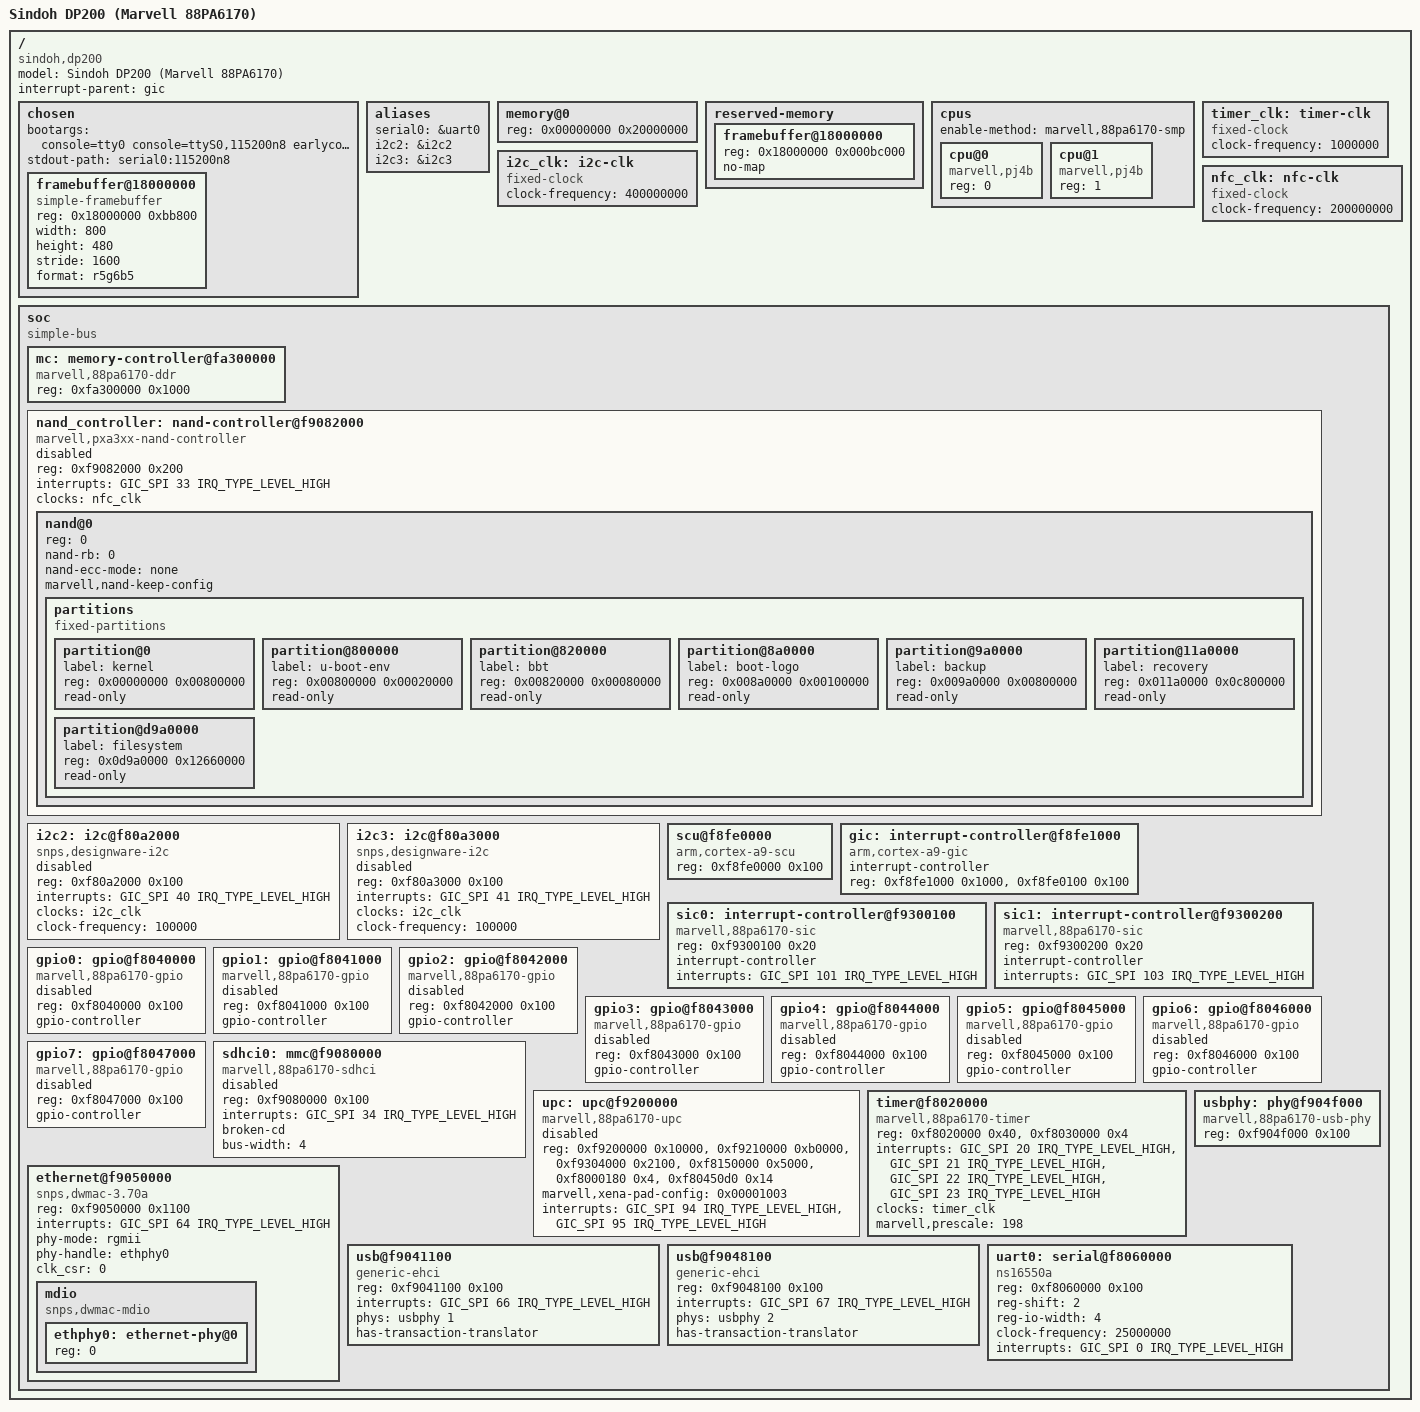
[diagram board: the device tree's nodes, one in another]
// SPDX-License-Identifier: GPL-2.0
/*
 * Sindoh DP200 3D printer, Marvell 88PA6170 SoC: milestone 1 of the
 * mainline route (klipper_port/docs/no_gpl_plan.md). One CPU, GIC, SoC
 * timer, UART0, built-in initramfs.
 *
 * Addresses and IRQs come from the vendor 3.2 kernel image
 * (tools/kernel_re/, docs/kernel/vendor_hwtables.txt). The vendor kernel
 * numbers IRQs as GIC IDs, so GIC_SPI n = vendor IRQ n - 32.
 *
 * Boot: zImage with this DTB appended (ARM_APPENDED_DTB +
 * ARM_ATAG_DTB_COMPAT), wrapped by mkimage for "bootm" in U-Boot 2011.09.
 * U-Boot's bootargs are appended to the bootargs below.
 */
/dts-v1/;

#include <dt-bindings/interrupt-controller/arm-gic.h>
#include <dt-bindings/interrupt-controller/irq.h>

/ {
	model = "Sindoh DP200 (Marvell 88PA6170)";
	compatible = "sindoh,dp200", "marvell,88pa6170";
	#address-cells = <1>;
	#size-cells = <1>;
	interrupt-parent = <&gic>;

	chosen {
		#address-cells = <1>;
		#size-cells = <1>;
		ranges;

		/* console=ttyS0 last: it stays /dev/console, tty0 is the panel */
		bootargs = "console=tty0 console=ttyS0,115200n8 earlycon=uart8250,mmio32,0xf8060000 rdinit=/init panic=10";
		stdout-path = "serial0:115200n8";

		/*
		 * The boot-logo buffer U-Boot set up and the LCD controller
		 * (0xf9070000) still scans: 800x480 RGB565, the panel mounted
		 * in portrait (fbcon=rotate:N turns the console).
		 */
		framebuffer@18000000 {
			compatible = "simple-framebuffer";
			reg = <0x18000000 0xbb800>;
			width = <800>;
			height = <480>;
			stride = <1600>;
			format = "r5g6b5";
		};
	};

	aliases {
		serial0 = &uart0;
		i2c2 = &i2c2;
		i2c3 = &i2c3;
	};

	memory@0 {
		device_type = "memory";
		reg = <0x00000000 0x20000000>;	/* 512 MB; U-Boot's ATAG_MEM replaces it */
	};

	reserved-memory {
		#address-cells = <1>;
		#size-cells = <1>;
		ranges;

		/* Boot-logo framebuffer set up by U-Boot, still scanned out */
		framebuffer@18000000 {
			reg = <0x18000000 0x000bc000>;
			no-map;
		};
	};

	cpus {
		#address-cells = <1>;
		#size-cells = <0>;
		/* SCU on, secondary_startup to the 0xfa000000 mailbox, SGI */
		enable-method = "marvell,88pa6170-smp";

		/* PJ4B-MP, MIDR 0x562f5841, MPIDR 0x80000000/1 */
		cpu@0 {
			device_type = "cpu";
			compatible = "marvell,pj4b";
			reg = <0>;
		};

		cpu@1 {
			device_type = "cpu";
			compatible = "marvell,pj4b";
			reg = <1>;
		};
	};

	/* Timer tick after the prescaler: 198 MHz bus / 198 */
	timer_clk: timer-clk {
		compatible = "fixed-clock";
		#clock-cells = <0>;
		clock-frequency = <1000000>;
	};

	/* vendor i2c_clk2/i2c_clk3: 400 MHz */
	i2c_clk: i2c-clk {
		compatible = "fixed-clock";
		#clock-cells = <0>;
		clock-frequency = <400000000>;
	};

	/*
	 * NAND controller clock: the bus clock. The NAND chip node keeps
	 * U-Boot's timing registers (marvell,nand-keep-config), so the
	 * driver never derives timings from this rate.
	 */
	nfc_clk: nfc-clk {
		compatible = "fixed-clock";
		#clock-cells = <0>;
		clock-frequency = <200000000>;
	};

	soc {
		compatible = "simple-bus";
		#address-cells = <1>;
		#size-cells = <1>;
		ranges;

		/*
		 * DDR controller. The vendor kernel writes 0x01010101 to +0x530
		 * on every mb() (its "outer cache sync"); mv61x0.c does the same
		 * from soc_mb when this node is enabled. On, as in stock: the A/B
		 * test showed no measurable cost (docs/kernel/mcsync_ab_test.md).
		 */
		mc: memory-controller@fa300000 {
			compatible = "marvell,88pa6170-ddr";
			reg = <0xfa300000 0x1000>;
		};

		/*
		 * PXA3xx-style NAND controller (vendor mv61x0_nand, IRQ 65)
		 * with a Macronix MX30LF4G18AC (c2:dc, 512 MiB, 2 KiB pages).
		 * The nand variant enables it with CONFIG_MTD_RAW_NAND_READ_ONLY
		 * (patch 0006): the chip is registered as ROM, nand_base write,
		 * erase and mark-bad paths return -EROFS, and the controller
		 * driver refuses program/erase/SET_FEATURES commands. ECC is off
		 * (raw page reads) until the vendor's ECC layout is known. No
		 * on-flash BBT. Partitions as the stock mtdparts, all read-only.
		 */
		nand_controller: nand-controller@f9082000 {
			compatible = "marvell,pxa3xx-nand-controller";
			reg = <0xf9082000 0x200>;
			interrupts = <GIC_SPI 33 IRQ_TYPE_LEVEL_HIGH>;
			clocks = <&nfc_clk>;
			#address-cells = <1>;
			#size-cells = <0>;
			status = "disabled";

			nand@0 {
				reg = <0>;
				nand-rb = <0>;
				nand-ecc-mode = "none";
				marvell,nand-keep-config;

				partitions {
					compatible = "fixed-partitions";
					#address-cells = <1>;
					#size-cells = <1>;

					partition@0 {
						label = "kernel";
						reg = <0x00000000 0x00800000>;
						read-only;
					};
					partition@800000 {
						label = "u-boot-env";
						reg = <0x00800000 0x00020000>;
						read-only;
					};
					partition@820000 {
						label = "bbt";
						reg = <0x00820000 0x00080000>;
						read-only;
					};
					partition@8a0000 {
						label = "boot-logo";
						reg = <0x008a0000 0x00100000>;
						read-only;
					};
					partition@9a0000 {
						label = "backup";
						reg = <0x009a0000 0x00800000>;
						read-only;
					};
					partition@11a0000 {
						label = "recovery";
						reg = <0x011a0000 0x0c800000>;
						read-only;
					};
					partition@d9a0000 {
						label = "filesystem";
						reg = <0x0d9a0000 0x12660000>;
						read-only;
					};
				};
			};
		};

		/*
		 * DesignWare I2C (vendor i2c_designware.2/.3). Bus 2 carries
		 * the touch controller (ROHM BU21029GUL, address 0x40, IRQ via
		 * GPIO); bus 3 the filament cartridge chip ("Smart-IC", 0x30),
		 * which stays disabled.
		 */
		i2c2: i2c@f80a2000 {
			compatible = "snps,designware-i2c";
			reg = <0xf80a2000 0x100>;
			interrupts = <GIC_SPI 40 IRQ_TYPE_LEVEL_HIGH>;
			clocks = <&i2c_clk>;
			clock-frequency = <100000>;
			#address-cells = <1>;
			#size-cells = <0>;
			status = "disabled";
		};

		i2c3: i2c@f80a3000 {
			compatible = "snps,designware-i2c";
			reg = <0xf80a3000 0x100>;
			interrupts = <GIC_SPI 41 IRQ_TYPE_LEVEL_HIGH>;
			clocks = <&i2c_clk>;
			clock-frequency = <100000>;
			#address-cells = <1>;
			#size-cells = <0>;
			status = "disabled";
		};

		/* A9-style private region: SCU +0, GIC CPU +0x100, GIC dist +0x1000 */
		scu@f8fe0000 {
			compatible = "arm,cortex-a9-scu";
			reg = <0xf8fe0000 0x100>;
		};

		gic: interrupt-controller@f8fe1000 {
			compatible = "arm,cortex-a9-gic";
			#interrupt-cells = <3>;
			interrupt-controller;
			reg = <0xf8fe1000 0x1000>,
			      <0xf8fe0100 0x100>;
		};

		/*
		 * Secondary interrupt controllers, 32 inputs each: vendor IRQs
		 * 145-176 (SIC0, parent 133) and 177-208 (SIC1, parent 135).
		 * SIC0 inputs 0-7 are the DEC timers at 0xf9300500.
		 */
		sic0: interrupt-controller@f9300100 {
			compatible = "marvell,88pa6170-sic";
			reg = <0xf9300100 0x20>;
			interrupt-controller;
			#interrupt-cells = <1>;
			interrupts = <GIC_SPI 101 IRQ_TYPE_LEVEL_HIGH>;
		};

		sic1: interrupt-controller@f9300200 {
			compatible = "marvell,88pa6170-sic";
			reg = <0xf9300200 0x20>;
			interrupt-controller;
			#interrupt-cells = <1>;
			interrupts = <GIC_SPI 103 IRQ_TYPE_LEVEL_HIGH>;
		};

		/*
		 * GPIO banks A-H, 32 lines each (input +0, output +4,
		 * direction +8, pin configuration +0x80). Disabled here; the
		 * gpio variant enables them. Nothing is driven at probe.
		 */
		gpio0: gpio@f8040000 {
			compatible = "marvell,88pa6170-gpio";
			reg = <0xf8040000 0x100>;
			gpio-controller;
			#gpio-cells = <2>;
			status = "disabled";
		};

		gpio1: gpio@f8041000 {
			compatible = "marvell,88pa6170-gpio";
			reg = <0xf8041000 0x100>;
			gpio-controller;
			#gpio-cells = <2>;
			status = "disabled";
		};

		gpio2: gpio@f8042000 {
			compatible = "marvell,88pa6170-gpio";
			reg = <0xf8042000 0x100>;
			gpio-controller;
			#gpio-cells = <2>;
			status = "disabled";
		};

		gpio3: gpio@f8043000 {
			compatible = "marvell,88pa6170-gpio";
			reg = <0xf8043000 0x100>;
			gpio-controller;
			#gpio-cells = <2>;
			status = "disabled";
		};

		gpio4: gpio@f8044000 {
			compatible = "marvell,88pa6170-gpio";
			reg = <0xf8044000 0x100>;
			gpio-controller;
			#gpio-cells = <2>;
			status = "disabled";
		};

		gpio5: gpio@f8045000 {
			compatible = "marvell,88pa6170-gpio";
			reg = <0xf8045000 0x100>;
			gpio-controller;
			#gpio-cells = <2>;
			status = "disabled";
		};

		gpio6: gpio@f8046000 {
			compatible = "marvell,88pa6170-gpio";
			reg = <0xf8046000 0x100>;
			gpio-controller;
			#gpio-cells = <2>;
			status = "disabled";
		};

		gpio7: gpio@f8047000 {
			compatible = "marvell,88pa6170-gpio";
			reg = <0xf8047000 0x100>;
			gpio-controller;
			#gpio-cells = <2>;
			status = "disabled";
		};

		/*
		 * SD socket (vendor mmc0; the second slot at 0xf9080200 shares
		 * the interrupt and stays out). Card detect does not work
		 * (vendor quirk), so the slot is polled. Disabled here; the sd
		 * variant enables it.
		 */
		sdhci0: mmc@f9080000 {
			compatible = "marvell,88pa6170-sdhci";
			reg = <0xf9080000 0x100>;
			interrupts = <GIC_SPI 34 IRQ_TYPE_LEVEL_HIGH>;
			broken-cd;
			bus-width = <4>;
			status = "disabled";
		};

		/*
		 * UPC coprocessors (the Klipper MCUs): ITCM 0 + XENA registers,
		 * ITCM 1 + DTCM, the dec_pwm and stepper engine blocks the
		 * driver forces off on probe, reboot and panic, and the APB
		 * config word whose UPC clock field it sets like stock. Disabled here;
		 * the upc variant enables it.
		 */
		upc: upc@f9200000 {
			compatible = "marvell,88pa6170-upc";
			reg = <0xf9200000 0x10000>, <0xf9210000 0xb0000>,
			      <0xf9304000 0x2100>, <0xf8150000 0x5000>,
			      <0xf8000180 0x4>, <0xf80450d0 0x14>;
			reg-names = "upc0", "upc1", "pwm", "smot", "apb",
				    "xena-pads";
			/*
			 * xena-pads: GPIO bank 5 pin selects 20-24, the X, Y
			 * (Z) endstop and cartridge-lever pads. Function 3
			 * routes them to the XENA inputs (user-approved,
			 * UPC test 2c); the driver sets them only with the
			 * cores held and every output off.
			 */
			marvell,xena-pad-config = <0x00001003>;
			interrupts = <GIC_SPI 94 IRQ_TYPE_LEVEL_HIGH>,
				     <GIC_SPI 95 IRQ_TYPE_LEVEL_HIGH>;
			status = "disabled";
		};

		/*
		 * Timers 0-3 (timer 0 is the vendor's watchdog). Timer 1 is the
		 * clock event device, timer 2 the clocksource. The second range
		 * is the prescaler, set to 198 like the vendor kernel does
		 * (BUSFREQ=200000000, "dithered" to 198 MHz).
		 */
		timer@f8020000 {
			compatible = "marvell,88pa6170-timer";
			reg = <0xf8020000 0x40>, <0xf8030000 0x4>;
			interrupts = <GIC_SPI 20 IRQ_TYPE_LEVEL_HIGH>,
				     <GIC_SPI 21 IRQ_TYPE_LEVEL_HIGH>,
				     <GIC_SPI 22 IRQ_TYPE_LEVEL_HIGH>,
				     <GIC_SPI 23 IRQ_TYPE_LEVEL_HIGH>;
			clocks = <&timer_clk>;
			marvell,prescale = <198>;
		};

		/*
		 * Synopsys GMAC (vendor driver: synopGMAC), DMA at +0x1000.
		 * Marvell 88E1510 RGMII PHY at MDIO address 0, held in reset
		 * by GPIO 62 (bank B bit 30) until the vendor kernel releases
		 * it (mach_phyHWInit); nothing here touches that GPIO. The
		 * vendor runs MDIO with CR = 0 and never sets the PHY's RGMII
		 * delays, so the PHY is bound to phylib's generic driver
		 * (MARVELL_PHY off), which keeps the strap defaults.
		 */
		ethernet@f9050000 {
			compatible = "snps,dwmac-3.70a", "snps,dwmac";
			reg = <0xf9050000 0x1100>;
			interrupts = <GIC_SPI 64 IRQ_TYPE_LEVEL_HIGH>;
			interrupt-names = "macirq";
			phy-mode = "rgmii";
			phy-handle = <&ethphy0>;
			clk_csr = <0>;

			mdio {
				compatible = "snps,dwmac-mdio";
				#address-cells = <1>;
				#size-cells = <0>;

				ethphy0: ethernet-phy@0 {
					reg = <0>;
				};
			};
		};

		/* PHYs 0-2 serve the device, host and OTG controllers */
		usbphy: phy@f904f000 {
			compatible = "marvell,88pa6170-usb-phy";
			reg = <0xf904f000 0x100>;
			#phy-cells = <1>;
		};

		/*
		 * ChipIdea controllers run as EHCI hosts, capability registers
		 * at +0x100 (vendor: "Marvell mv61xx EHCI"). ehci.0 is the
		 * host controller, ehci.1 the OTG controller in host mode.
		 */
		usb@f9041100 {
			compatible = "generic-ehci";
			reg = <0xf9041100 0x100>;
			interrupts = <GIC_SPI 66 IRQ_TYPE_LEVEL_HIGH>;
			phys = <&usbphy 1>;
			has-transaction-translator;
		};

		usb@f9048100 {
			compatible = "generic-ehci";
			reg = <0xf9048100 0x100>;
			interrupts = <GIC_SPI 67 IRQ_TYPE_LEVEL_HIGH>;
			phys = <&usbphy 2>;
			has-transaction-translator;
		};

		/*
		 * A DesignWare APB UART 3.08* (CPR 0x80013532: 16-byte FIFOs,
		 * AFCE, THRE, no shadow registers). The vendor runs it as a
		 * plain 16550A and so does milestone 1; "snps,dw-apb-uart" with
		 * SERIAL_8250_DW would add the busy-detect handling.
		 */
		uart0: serial@f8060000 {
			compatible = "ns16550a";
			reg = <0xf8060000 0x100>;
			reg-shift = <2>;
			reg-io-width = <4>;
			clock-frequency = <25000000>;
			interrupts = <GIC_SPI 0 IRQ_TYPE_LEVEL_HIGH>;
		};
	};
};
